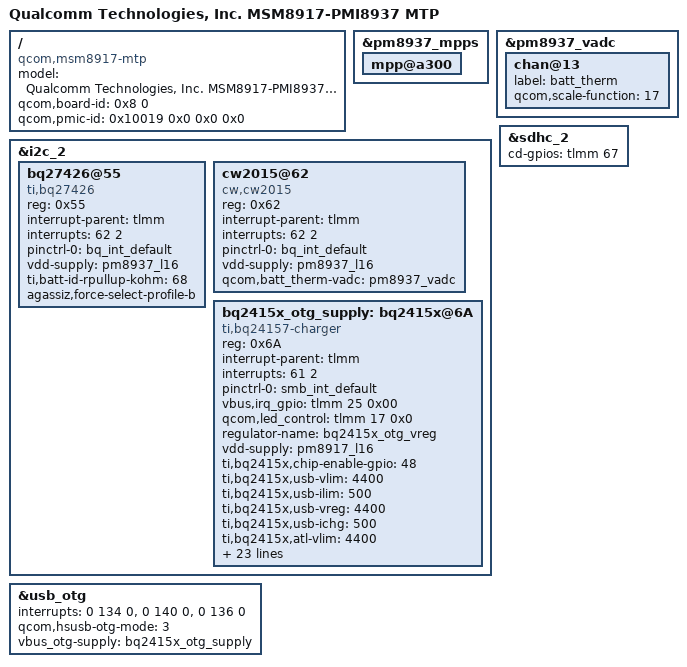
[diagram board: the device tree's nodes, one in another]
/*
 * Copyright (c) 2015-2016, The Linux Foundation. All rights reserved.
 *
 * This program is free software; you can redistribute it and/or modify
 * it under the terms of the GNU General Public License version 2 and
 * only version 2 as published by the Free Software Foundation.
 *
 * This program is distributed in the hope that it will be useful,
 * but WITHOUT ANY WARRANTY; without even the implied warranty of
 * MERCHANTABILITY or FITNESS FOR A PARTICULAR PURPOSE.  See the
 * GNU General Public License for more details.
 */

/dts-v1/;

#include "msm8917.dtsi"
#include "msm8917-pmi8937-mtp.dtsi"
#include "msm8937-regulator.dtsi"

/ {
	model = "Qualcomm Technologies, Inc. MSM8917-PMI8937 MTP";
	compatible = "qcom,msm8917-mtp", "qcom,msm8917", "qcom,mtp";
	qcom,board-id= <0x8 0>;
	qcom,pmic-id = <0x10019 0x0 0x0 0x0>;
};

&pm8937_mpps {
	mpp@a300 { /*MPP_04 for ADC*/
		status = "okay";
	};
};

&pm8937_vadc {
	chan@13 {
		label = "batt_therm";
		qcom,scale-function = <17>;//SCALE_THERM_10K_PULLUP

		status = "okay";
	};
};

&i2c_2 {
	status = "ok";
	//clock-frequency = <100000>;

	bq27426@55 {
		compatible = "ti,bq27426";
		reg = <0x55>;
		interrupt-parent = <&tlmm>;
		interrupts = <62 2>;
		pinctrl-names = "default";
		pinctrl-0 = <&bq_int_default>;

		vdd-supply = <&pm8937_l16>;
		ti,batt-id-rpullup-kohm = <68>;

		agassiz,force-select-profile-b;
		};

	cw2015@62 {
		compatible = "cw,cw2015";
		reg = <0x62>;
		interrupt-parent = <&tlmm>;
		interrupts = <62 2>;
		pinctrl-names = "default";
		pinctrl-0 = <&bq_int_default>;

		vdd-supply = <&pm8937_l16>;
		qcom,batt_therm-vadc = <&pm8937_vadc>;
		};

	bq2415x_otg_supply: bq2415x@6A {
		compatible = "ti,bq24157-charger";
		reg = <0x6A>;
		interrupt-parent = <&tlmm>;
		interrupts = <61 2>;
		pinctrl-names = "default";
		pinctrl-0 = <&smb_int_default>;

		//interrupt-parent = <&tlmm>;
		//interrupts = <25 2>;
		//pinctrl-names = "vbus_int";
		//pinctrl-0 = <&vbus_int_default>;

		vbus,irq_gpio = <&tlmm 25 0x00>;
		qcom,led_control = <&tlmm 17 0x0>;

		regulator-name = "bq2415x_otg_vreg";
		vdd-supply = <&pm8917_l16>;

		ti,bq2415x,chip-enable-gpio = <48>;
		ti,bq2415x,usb-vlim = <4400>;
		ti,bq2415x,usb-ilim = <500>;
		ti,bq2415x,usb-vreg = <4400>;
		ti,bq2415x,usb-ichg = <500>;

		ti,bq2415x,atl-vlim = <4400>;
		ti,bq2415x,atl-ilim = <1300>;
		ti,bq2415x,atl-vreg = <4400>;
		ti,bq2415x,atl-ichg = <1200>;
		ti,bq2415x,chg-resistor = <56>;


		ti,bq2415x,precharge-current = <256>;
		ti,bq2415x,termination-current = <128>;
		ti,bq2415x,boost-voltage = <4998>;
		ti,bq2415x,boost-current = <1200>;
		ti,bq2415x,enable_term;
		ti,bq2415x,stat-pin-ctrl = <0>;
		ti,bq2415x,vac-ovp-threshold = <6500>;

		ti,bq2415x,jeita-hot-degc = <570>;
		ti,bq2415x,jeita-warm-degc = <450>;
		ti,bq2415x,jeita-cool-degc = <150>;
		ti,bq2415x,jeita-cold-degc = <0>;

		ti,bq2415x,jeita-hot-hysteresis = <70>;
		ti,bq2415x,jeita-cold-hysteresis = <50>;

		ti,bq2415x,jeita-cool-ma = <500>;
		ti,bq2415x,jeita-cool-mv = <4400>;
		ti,bq2415x,jeita-warm-ma = <800>;
		ti,bq2415x,jeita-warm-mv = <4100>;

		ti,bq2415x,software-jeita-supported;
		qcom,thermal-mitigation = <1000 800 500 0>;
	};
};
&usb_otg{
	interrupts = <0 134 0>,<0 140 0>,<0 136 0>;
	interrupt-names = "core_irq", "async_irq", "phy_irq";

	qcom,hsusb-otg-mode = <3>; /* 1 peripheral mode*/
	//qcom,usbid-gpio = <&msm_gpio 41 0>;
	//qcom,usbid-gpio = <&tlmm 48 0x00>;
	//qcom,usbid-switch = <&msm_gpio 38 0>;
	//pinctrl-names = "default";
	//pinctrl-0 = <&usbid_default>;
	vbus_otg-supply = <&bq2415x_otg_supply>;

};

&sdhc_2 {
	cd-gpios = <&tlmm 67 0x0>;
};
